# YTM32B1ME0 register map
Vendor: YTMicro; File version: 1.6
CPU: CM33 r0p4, little endian, MPU, FPU, 2 interrupt priority bits
Registers are 32-bit, read-write, reset 0x0 unless marked. A register's access mark holds for its fields unless they carry their own. Offsets are from the block's base; [hi:lo] are bit positions; {n}, {i} and the like mark numbered series; 'fields as' and 'values as' point back to an identical list.

## CAN0 (part 1 of 4) — FlexCAN module
Base 0x40030000; register names take the prefix CAN0_
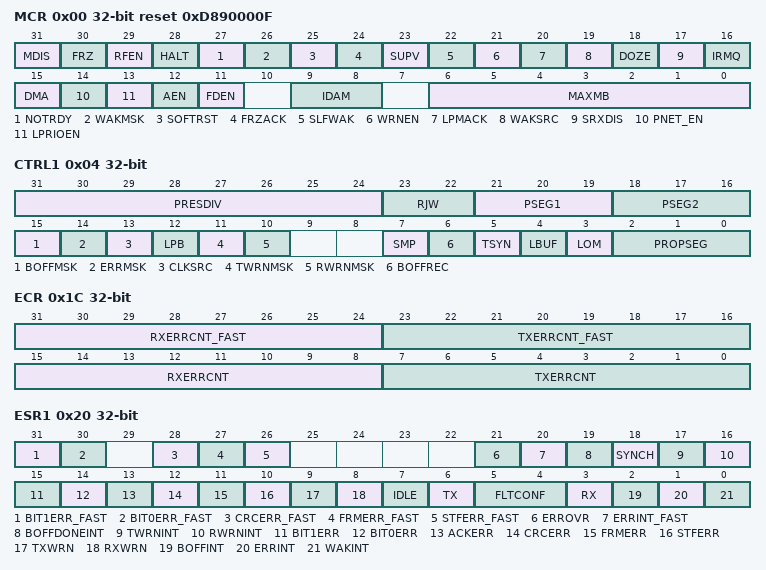
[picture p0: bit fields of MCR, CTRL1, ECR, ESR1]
0x00 MCR reset 0xD890000F — CAN_MCR defines global system configurations, such as the module operation modes and the maximum message buffer configuration.
  [31] MDIS — When disabled, the FlexCAN disables the clocks to the PE and CHI submodules. MDIS is not affected by soft reset.
    0=Enable the FlexCAN module; 1=Disable the FlexCAN module
  [30] FRZ — The FRZ bit specifies the FlexCAN behavior when CAN_MCR.HALT is set or when Debug mode is requested at chip level. When FRZ is asserted, the FlexCAN is enabled to enter Freeze mode. Negation of FRZ causes the FlexCAN to exit from Freeze mode. FRZ is set by hardware when a non-correctable error is detected and CAN_MECR.NCEFAFRZ is asserted.
    0=Not enabled to enter freeze mode; 1=Enabled to enter freeze mode
  [29] RFEN — When RFEN is set, MBs 0-5 cannot be used for normal reception and transmission because the corresponding memory region (0x80-0xDC) is used by the FIFO engine and additional MBs (up to 32, depending on CAN_CTRL2.RFFN setting), which are used as Legacy Rx FIFO ID Filter Table elements. RFEN also impacts the minimum number of peripheral clocks per CAN bit. RFEN can be written in Freeze mode only because it is blocked by hardware in other modes. NOTE: RFEN cannot be set when CAN FD operation is enabled (see FDEN bit).
    0=Disable Rx FIFO; 1=Enable Rx FIFO
  [28] HALT — Assertion of HALT puts the FlexCAN module into Freeze mode. The CPU should clear HALT after initializing the message buffers and the control registers CAN_CTRL1 and CAN_CTRL2. No reception or transmission is performed by the FlexCAN before HALT is cleared. Freeze mode cannot be entered when the FlexCAN is in a low-power mode. The HALT bit is set by hardware when a non-correctable error is detected and CAN_MECR.NCEFAFRZ is asserted.
    0=No Freeze mode request; 1=Enter Freeze mode if the FRZ bit is asserted
  [27] NOTRDY ro — NOTRDY is a read-only bit that indicates that the FlexCAN is either in Module Disable, Doze, Deepsleep, or Freeze mode. NOTRDY is negated when the FlexCAN has exited these modes. NOTRDY bit is not affected by soft reset
    0=FlexCAN is either in Normal, Listen-Only or Loop-Back mode; 1=FlexCAN is either in Module Disable, Doze, Deepsleep or Freeze mode
  [26] WAKMSK — Enables Wake Up interrupt generation under the Self Wake Up mechanism:
    0=Disable Wake Up interrupt; 1=Enable Wake Up interrupt
  [25] SOFTRST — When SOFTRST is asserted, the FlexCAN resets its internal state machines and some of the memory-mapped registers. SOFTRST can be asserted directly by the CPU by writing to CAN_MCR. SOFTRST is also asserted when global soft reset is requested at chip level. Because soft reset is synchronous and has to follow a request/acknowledge procedure across clock domains, it may take some time to fully propagate its effect. The SOFTRST bit remains asserted while reset is pending, and is automatically negated when reset completes. Therefore, software can poll SOFTRST to know when the soft reset has completed. Soft reset cannot be applied when clocks are shut down in a low-power mode. The FlexCAN should be first removed from low-power mode, then soft reset can be applied. SOFTRST is not affected by soft reset
    0=No reset request; 1=Reset the registers affected by software reset
  [24] FRZACK ro — FRZACK is a read-only bit that indicates that the FlexCAN is in Freeze mode and its prescaler is stopped. A Freeze mode request cannot be granted until current transmission or reception processes have finished. Therefore, software can poll FRZACK to know when the FlexCAN has actually entered Freeze mode. If the Freeze mode request is negated, FRZACK is negated after the FlexCAN prescaler is running again. If Freeze mode is requested when the FlexCAN is in a low-power mode, FRZACK will be set only when the low-power mode is exited. See \hyperref[freeze-mode]{"Freeze Mode"}. FRZACK is not affected by soft reset. NOTE: FRZACK is asserted within 178 CAN bits from the Freeze mode request by the CPU, and negated within 2 CAN bits after the Freeze mode request removal (see \hyperref[protocol-timing]{"Protocol Timing"}).
    0=FlexCAN not in Freeze Mode, prescaler running; 1=FlexCAN in Freeze Mode, prescaler stopped
  [23] SUPV — The registers affected by SUPV are marked as S/U in the Access Type column of Table: \hyperref[CAN-register-access-and-reset-information]{"CAN register access and reset information"}. The SUPV reset value is 1, so the affected registers start with Supervisor access only. SUPV can be written only in Freeze mode because it is blocked by hardware in other modes.
    1=FlexCAN is in Supervisor Mode, Affected registers allow only Supervisor access. Unrestricted access behaves as though the access was done to an unimplemented register location.; 0=FlexCAN is in User mode, Affected registers allow both Supervisor and Unrestricted accesses
  [22] SLFWAK — When the Self Wake Up feature is enabled, the FlexCAN module monitors the bus for wakeup event (a recessive-to-dominant transition). If a wakeup event is detected during Deepsleep mode, the FlexCAN, if enabled to do so, generates a Wake Up interrupt to the CPU so that it can exit Deepsleep mode globally and the FlexCAN can request to resume the clocks. When FlexCAN is in a low-power mode other than Module Disable, SLFWAK cannot be written as it is blocked by hardware. When Pretended Networking mode is set, Self Wake Up must be disabled.
    1=Enable FlexCAN self Wake Up feature; 0=Disable FlexCAN self Wake Up feature
  [21] WRNEN — Assertion of WRNEN enables the generation of the TWRNINT and RWRNINT flags in the Error and Status Register 1 (CAN_ESR1). If WRNEN is negated, the TWRNINT and RWRNINT flags will always be zero, independent of the values of the error counters, and no warning interrupt will ever be generated. WRNEN can be written only in Freeze mode because it is blocked by hardware in other modes.
    1=TWRNINT and RWRNINT bits are set when the respective error counter transitions from less than 96 to greater than or equal to 96; 0=TWRNINT and RWRNINT bits are zero, independent of the values in the error counters
  [20] LPMACK ro — LPMACK is a read-only bit that indicates that the FlexCAN is in a low-power mode (Module Disable, Doze or Deepsleep). A low-power mode cannot be entered until all current transmission or reception processes have finished. Therefore, the CPU can poll LPMACK to know when the FlexCAN has actually entered low-power mode. LPMACK is not affected by soft reset. NOTE: LPMACK is asserted within 180 CAN bits from the low-power mode request by the CPU, and negated within 2 CAN bits after the low-power mode request removal (see \hyperref[protocol-timing]{"Protocol Timing"}). When the FlexCAN is in Pretended Networking mode, LPMACK is negated within 180 CAN bits after the low-power mode request removal.
    1=FlexCAN is in the low-power mode; 0=FlexCAN is not in the low-power mode
  [19] WAKSRC — WAKSRC can be written only in Freeze mode because it is blocked by hardware in other modes.
    1=FlexCAN uses the filtered RX input to detect recessive to dominant edges on the can bus; 0=FlexCAN uses the unfiltered RX input to detect recessive to dominant edges on the can bus
  [18] DOZE — DOZE is automatically reset when the FlexCAN wakes up from Doze mode upon detecting activity on the CAN bus (Self Wake Up enabled).
    1=FlexCAN is enabled to enter low-power mode when Doze mode is requested; 0=FlexCAN is not enabled to enter low-power mode when Doze mode is requested
  [17] SRXDIS — SRXDIS controls whether the FlexCAN is allowed to receive frames transmitted by itself. If SRXDIS is asserted, frames transmitted by the FlexCAN are not stored in any MB, regardless of whether the MB is programmed with an ID that matches the transmitted frame, and no interrupt flag or interrupt signal is generated due to the frame reception. SRXDIS can be written only in Freeze mode because it is blocked by hardware in other modes
    1=Disable self-reception; 0=Enable self-reception
  [16] IRMQ — IRMQ controls whether Rx matching process is based on individual masking and queue or on masking scheme with CAN_RXMGMASK, CAN_RX14MASK, CAN_RX15MASK, and CAN_RXFGMASK. IRMQ can be written in Freeze mode only because it is blocked by hardware in other modes.
    1=Enable individual Rx masking and queue feature; 0=Disable individual Rx masking and queue feature. For backward compatibility with legacy applications, the reading of C/S word locks the MB even if it is EMPTY
  [15] DMA — The DMA bit enables or disables the DMA feature. The DMA feature can only be used with the Legacy Rx FIFO or the Enhanced Rx FIFO; consequently, either CAN_MCR.RFEN or CAN_ERFCR.ERFEN must be asserted. When DMA and RFEN are both set, CAN_IFLAG1.BUF5I generates the DMA request and no Rx FIFO interrupt is generated. The DMA bit can be written in Freeze mode only as it is blocked by hardware in other modes. The DMA bit is not available(reserved, write 0) if parameter DMA_EN is 0
    1=Enable DMA feature for Rx FIFO; 0=Disable DMA feature for Rx FIFO
  [14] PNET_EN — When Pretended Networking is enabled, the PE submodule is kept operational in Doze mode and Deepsleep mode, so that it is able to process Rx message filtering as defined by the Pretended Networking configuration registers. See \hyperref[receive-process-under-pretended-networking-mode]{"Receive Process under Pretended Networking Mode"}. PNET_EN can be written in Freeze mode only. The PNET_EN bit is not available (reserved, write 0) if parameter PNET_EN is 0.
    1=Enable Pretended Networking mode; 0=Disable Pretended Networking mode
  [13] LPRIOEN — The LPRIOEN bit is provided for backward compatibility with legacy applications. LPRIOEN controls whether the Local Priority feature is enabled or not. Local Priority is used to expand the ID used during the arbitration process. With this expanded ID concept, the arbitration process is done based on the full 32-bit word, but the actual transmitted ID still has 11 bits for standard frames and 29 bits for extended frames. LPRIOEN can be written only in Freeze mode because it is blocked by hardware in other modes.
  [12] AEN — The Tx abort mechanism ensures a safe procedure for aborting a pending transmission, so that no frame is sent on the CAN bus without notification. See \hyperref[transmission-abort-mechanism]{"Transmission Abort Mechanism"}. AEN can be written only in Freeze mode because it is blocked by hardware in other modes. NOTE: When AEN is asserted, the abort mechanism must only be used for updating mailboxes configured for transmission. Caution: Writing the Abort code into Rx mailboxes can cause unpredictable results when AEN is asserted.
    1=Enable abort; 0=Disable abort
  [11] FDEN — FDEN can be written in Freeze mode only. The FEDN bit is not available (reserved, write 0) if parameter FD_EN is 0. NOTE: The Rx FIFO Enable (RFEN) bit cannot be set if FDEN is asserted.
    1=CAN FD is enabled. The FlexCAN is able to receive and transmit messages in both CAN FD and CAN 2.0 formats.; 0=CAN FD is disabled. The FlexCAN is able to receive and transmit messages in CAN 2.0 format.
  [9:8] IDAM — All elements of the table are configured at the same time by IDAM (they are all the same format). See \hyperref[legacy-rx-fifo-structure]{"Legacy Rx FIFO Structure"}. IDAM can be written only in Freeze mode because it is blocked by hardware in other modes.
    0=Format A – One full ID (standard and extended) per ID Filter Table element; 1=Format B – Two full standard IDs or two partial 14-bit (standard and extended) IDs per ID Filter Table element; 2=Format C – Four partial 8-bit standard IDs per ID Filter Table element; 3=Format D – All frames rejected
  [6:0] MAXMB — The reset value (0x0F) is equivalent to a 16 message buffer configuration. MAXMB can be written only in Freeze mode because it is blocked by hardware in other modes. Number of the last MB = MAXMB NOTE: MAXMB must be programmed with a value smaller than or equal to the number of available message buffers, as described in \hyperref[flexcan-memory-partition-for-can-fd]{"FlexCAN Memory Partition for CAN FD"}. Additionally, the definition of MAXMB value must take into account the region of MBs occupied by Rx FIFO and its ID filters table space defined by CAN_CTRL2.RFFN. MAXMB also impacts the minimum number of peripheral clocks per CAN bit as described in the FlexCAN Integration Guide.
0x04 CTRL1 — The CAN_CTRL1 register is defined for specific FlexCAN control features related to the CAN bus, such as bit-rate, programmable sampling point within an Rx bit, Loop-Back mode, Listen-Only mode, Bus Off recovery behavior, and interrupt enabling (Bus Off, Error, Warning). It also determines the division factor for the clock prescaler. The CAN bit timing variables (PRESDIV, PROPSEG, PSEG1, PSEG2, and RJW) can also be configured in CAN_CBT register, which extends the range of all these variables. If CAN_CBT.BTF is set, the PRESDIV, PROPSEG, PSEG1, PSEG2, and RJW fields of CAN_CTRL1 become read-only. When CAN_CTRL2.BTE = 1, the PRESDIV, PROPSEG, PSEG1, PSEG2, and RJW fields in CAN_CTRL1 are not used. They are read as zero and a write operation to them has no effect. NOTE: When the CAN FD feature is enabled, do not use the PRESDIV, RJW, PSEG1, PSEG2, and PROPSEG fields of the CAN_CTRL1 register for CAN bit timing. Instead, use the CAN_CBT register’s EPRESDIV, ERJW, EPSEG1, EPSEG2, and EPROPSEG fields. The contents of the CAN_CTRL1 register are not affected by soft reset. NOTE: The CAN bit variables in CAN_CTRL1 and in CAN_CBT are stored in the same register.
  [31:24] PRESDIV — The Sclock period defines the time quantum of the CAN protocol. For the reset value, the Sclock frequency is equal to the PE clock frequency. The maximum value of PRESDIV is 0xFF, which gives a minimum Sclock frequency equal to the PE clock frequency divided by 256. See section \hyperref[protocol-timing]{"Protocol Timing"}. PRESDIV can be written only in Freeze mode because it is blocked by hardware in other modes. Sclock frequency = PE clock frequency / (PRESDIV + 1)
  [23:22] RJW — One time quantum is equal to the Sclock period. The valid programmable values for RJW are 0–3. RJW can be written only in Freeze mode because it is blocked by hardware in other modes. Resync Jump Width = RJW + 1
  [21:19] PSEG1 — The valid programmable values are 0–7. PSEG1 can be written only in Freeze mode because it is blocked by hardware in other modes. Phase Buffer Segment 1 = (PSEG1 + 1) × Time-Quanta
  [18:16] PSEG2 — The valid programmable values are 1–7. PSEG2 can be written only in Freeze mode because it is blocked by hardware in other modes. Phase Buffer Segment 2 = (PSEG2 + 1) × Time-Quanta
  [15] BOFFMSK
    0=Bus Off interrupt disabled; 1=Bus Off interrupt enabled
  [14] ERRMSK
    0=Error interrupt disabled; 1=Error interrupt enabled
  [13] CLKSRC — The selected clock is fed to the prescaler to generate the serial clock (Sclock). To ensure reliable operation, CLKSRC can be written only in Disable mode. In other modes, writing to CLKSRC is blocked by hardware. See \hyperref[protocol-timing]{"Protocol Timing"}.
    0=The PE clock source is the oscillator clock. Under this condition, the oscillator clock frequency must be lower than the peripheral clock frequency.; 1=The PE clock source is the peripheral clock
  [12] LPB — In Loop-Back mode, the FlexCAN performs an internal loop back that can be used for self-test operation. The bit stream output of the transmitter is fed back internally to the receiver input. The Rx CAN input pin is ignored and the Tx CAN output goes to the recessive state (logic 1). The FlexCAN behaves as it normally does when transmitting, and treats its own transmitted message as a message received from a remote node. In Loop-Back mode, the FlexCAN ignores the bit sent during the ACK slot in the CAN frame acknowledge field, generating an internal acknowledge bit to ensure proper reception of its own message. Both transmit and receive interrupts are generated. LPB can be written only in Freeze mode because it is blocked by hardware in other modes. NOTE: In Loop-Back mode, CAN_MCR.SRXDIS cannot be asserted because it would impede the self-reception of a transmitted message. NOTE: CAN_FDCTRL.TDCEN must be 0 (Transceiver Delay Compensation feature disabled) when LPB is asserted.
    0=Loop-Back disabled; 1=Loop-Back enabled
  [11] TWRNMSK — TWRNMSK is read as zero when CAN_MCR.WRNEN is negated. TWRNMSK can be written only if CAN_MCR.WRNEN is asserted
    0=Tx Warning interrupt disabled; 1=Tx Warning interrupt enabled
  [10] RWRNMSK — RWRNMSK is read as zero when CAN_MCR.WRNEN is negated. RWRNMSK can be written only if CAN_MCR.WRNEN is asserted.
    0=Rx Warning interrupt disabled; 1=Rx Warning interrupt enabled
  [7] SMP — SMP can be written only in Freeze mode because it is blocked by hardware in other modes. NOTE: For proper operation, to assert SMP it is necessary to guarantee a minimum value of two time quanta in CAN_CTRL1.PSEG1 (or CAN_CBT.EPSEG1). SMP cannot be asserted when CAN FD is enabled (CAN_MCR.FDEN = 1).
    0=One sample is used to determine the bit value; 1=Three samples are used to determine the value of the received bit, the regular sample (sample point) and two preceding samples; a majority rule is used
  [6] BOFFREC — If BOFFREC is negated, automatic recovering from Bus Off state occurs according to the CAN Specification 2.0B. If BOFFREC is asserted, automatic recovering from Bus Off is disabled and the FlexCAN module remains in Bus Off state until BOFFREC is negated by software. If the negation occurs before 128 sequences of 11 recessive bits are detected on the CAN bus, then Bus Off recovery happens as if the BOFFREC bit had never been asserted. If the negation occurs after 128 sequences of 11 recessive bits occurred, then the FlexCAN will re-synchronize to the bus by waiting for 11 recessive bits before joining the bus. After negation, BOFFREC can be re-asserted again during Bus Off, but it will be effective only the next time the FlexCAN module enters Bus Off. If BOFFREC was negated when the FlexCAN module entered Bus Off, asserting BOFFREC during Bus Off will not be effective for the current Bus Off recovery.
    0=Automatic recovering from Bus Off state enabled; 1=Automatic recovering from Bus Off state disabled
  [5] TSYN — The Timer Sync feature provides a means to synchronize multiple FlexCAN stations with a special "SYNC" message (global network time). If CAN_MCR.RFEN is set (Legacy Rx FIFO enabled), the first available mailbox, according to the CAN_CTRL2.RFFN setting, is used for timer synchronization instead of MB0. TSYN can be written in Freeze mode only because it is blocked by hardware in other modes.
    0=Timer Sync feature disabled; 1=Timer Sync feature enabled
  [4] LBUF — When LBUF is asserted, the CAN_MCR.LPRIOEN bit does not affect the priority arbitration. LBUF can be written only in Freeze mode because it is blocked by hardware in other modes.
    0=Buffer with highest priority is transmitted first; 1=Lowest number buffer is transmitted first
  [3] LOM — In Listen-Only mode, transmission is disabled, all error counters described in CAN_ECR are frozen and the FlexCAN module operates in a CAN Error Passive mode. Only messages acknowledged by another CAN station will be received. If the FlexCAN detects a message that has not been acknowledged, it flags a BIT0 error without changing the receive error counter (RXERRCNT) in CAN_ECR, as if it were trying to acknowledge the message. Listen-Only mode is acknowledged by the state of the CAN_ESR1.FLTCONF field indicating Passive Error. There can be some delay between the Listen-Only mode request and acknowledge. LOM can be written in Freeze mode only because it is blocked by hardware in other modes.
    0=Listen-Only mode is deactivated; 1=FlexCAN module operates in Listen-Only mode
  [2:0] PROPSEG — The valid programmable values are 0–7. PROPSEG can be written only in Freeze mode because it is blocked by hardware in other modes. Propagation segment time = (PROPSEG + 1) × time-quanta. Time-quantum = one Sclock period.
0x08 TIMER — The CAN_TIMER register represents a 16-bit free-running counter that can be read and written by the CPU. The timer starts from 0x0 after reset, counts linearly to 0xFFFF, and wraps around. When CAN_CTRL2.TIMER_SRC is asserted, the timer is continuously incremented by an external time tick. The time tick must be synchronous to the peripheral clock, with a minimum pulse width of one ipg_clk cycle. When CAN_CTRL2.TIMER_SRC is negated, the timer is incremented by the CAN bit clock, which defines the baud rate on the CAN bus. During a message transmission/reception, the timer increments by one for each bit that is received or transmitted. When there is no message on the bus, the timer counts using the previously programmed baud rate. The timer is not incremented during Module Disable, Doze, Deepsleep, and Freeze modes. The timer value is captured when the second bit of the identifier field of any frame is on the CAN bus. This captured value is written into the Time Stamp entry in a message buffer after a successful reception or transmission of a message. If CAN_CTRL1.TSYN is asserted, the timer is reset whenever a message is received in the first available mailbox, according to the CAN_CTRL2.RFFN setting. The CPU can write to this register anytime. However, if the write occurs at the same time that the timer is being reset by a reception in the first mailbox, then the write value is discarded. Reading this register affects the mailbox unlocking procedure, see \hyperref[mailbox-lock-mechanism]{"Mailbox Lock Mechanism"}.
  [15:0] TIMER
0x10 RXMGMASK
  [31:0] MG — The MG bits mask the mailbox filter bits. Note that the alignment with the ID word of the mailbox is not perfect as the two most significant MG bits affect the fields RTR and IDE, which are located in the Control and Status (C/S) word of the mailbox. Details see table \hyperref[CAN-which-MG-bits-mask-each-mailbox-filter-field]{CAN which MG bits mask each mailbox filter field} 0b - The corresponding bit in the filter is ``don't care". 1b - The corresponding bit in the filter is checked.
0x14 RX14MASK — The CAN_RX14MASK register is located in RAM. CAN_RX14MASK is provided for legacy application support. When the CAN_MCR.IRMQ bit is asserted, CAN_RX14MASK has no effect. CAN_RX14MASK is used to mask the filter fields of message buffer 14. CAN_RX14MASK can only be programmed when the FlexCAN is in Freeze mode as it is blocked by hardware in other modes.
  [31:0] RX14M — Each mask bit masks the corresponding mailbox 14 filter field in the same way that CAN_RXMGMASK masks other mailboxes’ filters. See the description of the CAN_RXMGMASK register. 0b - The corresponding bit in the filter is ``don't care". 1b - The corresponding bit in the filter is checked.
0x18 RX15MASK — The CAN_RX15MASK register is located in RAM. CAN_RX15MASK is provided for legacy application support. When the CAN_MCR.IRMQ bit is asserted, CAN_RX15MASK has no effect. CAN_RX15MASK is used to mask the filter fields of message buffer 15. CAN_RX15MASK can be programmed only when the FlexCAN is in Freeze mode because it is blocked by hardware in other modes.
  [31:0] RX15M — Each mask bit masks the corresponding mailbox 15 filter field in the same way that CAN_RXMGMASK masks other mailboxes’ filters. See the description of the CAN_RXMGMASK register. 0b - The corresponding bit in the filter is ``don't care". 1b - The corresponding bit in the filter is checked.
0x1C ECR
  [31:24] RXERRCNT_FAST — Receive Error Counter for Fast Bits – Receive error counter for errors detected in the Data Phase of received CAN FD messages with the BRS bit set. The RXERRCNT_FAST counter is read-only except in Freeze mode, in which the CPU can write an 8-bit zero value only. RXERRCNT_FAST is not available (reserved) when configuration parameter FD_EN is 0.
  [23:16] TXERRCNT_FAST — Transmit Error Counter for Fast Bits – Transmit error counter for errors detected in the Data Phase of transmitted CAN FD messages with the BRS bit set. The TXERRCNT_FAST counter is read-only except in Freeze mode, in which the CPU can write a 8-bit zero value only. TXERRCNT_FAST is not available (reserved) when configuration parameter FD_EN is 0.
  [15:8] RXERRCNT — Receive Error Counter – Receive error counter for all errors detected in received messages. The RXERRCNT counter is read-only except in Freeze mode, in which it can be written by the CPU.
  [7:0] TXERRCNT — Transmit Error Counter – Transmit error counter for all errors detected in transmitted messages. The TXERRCNT counter is read-only except in Freeze mode, in which it can be written by the CPU.
0x20 ESR1
  [31] BIT1ERR_FAST ro — BIT1ERR_FAST indicates when an inconsistency occurs between the transmitted and the received bit in the Data Phase of CAN FD frames with the BRS bit set. BIT1ERR_FAST is not available (reserved) when configuration parameter FD_EN is 0.
    0=No such occurrence; 1=At least one bit sent as recessive is received as dominant
  [30] BIT0ERR_FAST ro — BIT0ERR_FAST indicates when an inconsistency occurs between the transmitted and the received bit in the Data Phase of CAN FD frames with the BRS bit set. BIT0ERR_FAST is not available (reserved) when configuration parameter FD_EN is 0.
    values as BIT1ERR_FAST
  [28] CRCERR_FAST ro — CRCERR_FAST indicates that a CRC error has been detected by the receiver node in the CRC field of CAN FD frames with the BRS bit set; that is, the calculated CRC is different from the received CRC. CRCERR_FAST is not available (reserved) when configuration parameter FD_EN is 0.
    0=No such occurrence; 1=A CRC error occurred since last read of this register
  [27] FRMERR_FAST ro — FRMERR_FAST indicates that a form error has been detected by the receiver node in the Data Phase of CAN FD frames with the BRS bit set; that is, a fixed-form bit field contains at least one illegal bit. FRMERR_FAST is not available (reserved) when configuration parameter FD_EN is 0.
    0=No such occurrence; 1=A form error occurred since last read of this register
  [26] STFERR_FAST ro — STFERR_FAST indicates that a stuffing error has been detected in the Data Phase of CAN FD frames with the BRS bit set. STFERR_FAST is not available (reserved) when configuration parameter FD_EN is 0.
    0=No such occurrence; 1=A stuffing error occurred since last read of this register
  [21] ERROVR — ERROVR is cleared by writing 1 to it.
    0=Overrun has not occurred; 1=Overrun has occurred
  [20] ERRINT_FAST — ERRINT_FAST indicates that at least one of the error bits detected in the Data Phase of CAN FD frames with the BRS bit set (BIT1ERR_FAST, BIT0ERR_FAST, CRCERR_FAST, FRMERR_FAST, or STFERR_FAST) is set. If the corresponding mask bit (CAN_CTRL2.ERRMSK_FAST) is set, an interrupt is generated to the CPU. ERRINT_FAST is cleared by writing 1 to it. Writing 0 has no effect. ERRINT_FAST is not available (reserved) when configuration parameter FD_EN is 0.
    0=No such occurrence; 1=Indicates setting of any error bit detected in the Data Phase of CAN FD frames with the BRS bit set
  [19] BOFFDONEINT — BOFFDONEINT is set when the Tx Error Counter (TXERRCNT) has finished counting 128 occurrences of 11 consecutive recessive bits on the CAN bus and is ready to leave Bus Off. If the corresponding mask bit (CAN_CTRL2.BOFFDONEMSK) is set, an interrupt is generated to the CPU. BOFFDONEINT is cleared by writing 1 to it. Writing 0 has no effect.
    0=No such occurrence; 1=FlexCAN module has completed Bus Off process
  [18] SYNCH ro — SYNCH is a read-only flag that indicates whether the FlexCAN is synchronized to the CAN bus and able to participate in the communication process. It is set and cleared by the FlexCAN. See \hyperref[CAN-state-related-bit-encodings]{CAN state related bit encodings}
    0=FlexCAN is not synchronized to the CAN bus; 1=FlexCAN is synchronized to the CAN bus
  [17] TWRNINT — If CAN_MCR.WRNEN is asserted, the TWRNINT bit is set when the TXWRN flag transitions from 0 to 1, meaning that the Tx error counter reached 96. If the corresponding mask bit (CAN_CTRL1.TWRNMSK) is set, an interrupt is generated to the CPU. TWRNINT is cleared by writing 1 to it. Writing 0 has no effect. When CAN_MCR.WRNEN is negated, the TWRNINT flag is masked. The CPU must clear the TWRNINT flag before negating CAN_MCR.WRNEN. Otherwise, TWRNINT will be set when CAN_MCR.WRNEN is set again. TWRNINT is not generated during the Bus Off state and is not updated during Freeze mode. When the FlexCAN returns to Normal mode from Pretended Networking mode, TWRNINT is not updated. See \hyperref[receive-process-under-pretended-networking-mode]{"Receive Process under Pretended Networking Mode"}.
    0=No such occurrence; 1=The Tx error counter transitioned from less than 96 to greater than or equal to 96
  [16] RWRNINT — If CAN_MCR.WRNEN is asserted, the RWRNINT bit is set when the RXWRN flag transitions from 0 to 1, meaning that the Rx error counters reached 96. If the corresponding mask bit (CAN_CTRL1.RWRNMSK) is set, an interrupt is generated to the CPU. RWRNINT is cleared by writing it to 1 to it. Writing 0 has no effect. When CAN_MCR.WRNEN is negated, the RWRNINT flag is masked. The CPU must clear the RWRNINT flag before negating CAN_MCR.WRNEN. Otherwise, RWRNINT will be set when CAN_MCR.WRNEN is set again. RWRNINT is not updated during Freeze mode. When the FlexCAN returns to Normal mode from Pretended Networking mode, RWRNINT is updated to reflect the Rx error counter state. See \hyperref[receive-process-under-pretended-networking-mode]{"Receive Process under Pretended Networking Mode"}
    0=No such occurrence; 1=The Rx error counter transitioned from less than 96 to greater than or equal to 96
  [15] BIT1ERR ro — NOTE: BIT1ERR is not set by a transmitter in case of arbitration field or ACK slot, or in case of a node sending a passive error flag that detects dominant bits. BIT1ERR is updated when the FlexCAN returns to Normal mode from Pretended Networking mode.
  [14] BIT0ERR ro — BIT0ERR is updated when the FlexCAN returns to Normal mode from Pretended Networking mode.
    0=No such occurrence; 1=At least one bit sent as dominant is received as recessive
  [13] ACKERR ro — ACKERR is updated when the FlexCAN returns to Normal mode from Pretended Networking mode.
    0=No such occurrence; 1=An ACK error occurred since last read of this register
  [12] CRCERR ro — CRCERR is updated when the FlexCAN returns to Normal mode from Pretended Networking mode.
    values as CRCERR_FAST
  [11] FRMERR ro — FRMERR is updated when the FlexCAN returns to Normal mode from Pretended Networking mode.
    values as FRMERR_FAST
  [10] STFERR ro — STFERR is updated when the FlexCAN returns to Normal mode from Pretended Networking mode.
    values as STFERR_FAST
  [9] TXWRN ro — TXWRN is affected by the value of CAN_ECR.TXERRCNT only. TXWRN is not updated during Freeze mode. TXWRN is updated when the FlexCAN returns to Normal mode from Pretended Networking mode.
    0=No such occurrence; 1=TXERRCNT is greater than or equal to 96
  [8] RXWRN ro — RXWRN is affected by the value of CAN_ECR.RXERRCNT only. RXWRN is not updated during Freeze mode. RXWRN is updated when the FlexCAN returns to Normal mode from Pretended Networking mode.
    0=No such occurrence; 1=RXERRCNT is greater than or equal to 96
  [7] IDLE ro — Indicates when the CAN bus is in the IDLE state. See \hyperref[CAN-state-related-bit-encodings]{CAN state related bit encodings}
    0=No such occurrence; 1=CAN bus is now IDLE
  [6] TX ro — Indicates if the FlexCAN is transmitting a message. See \hyperref[CAN-state-related-bit-encodings]{CAN state related bit encodings}
    0=FlexCAN is not transmitting a message; 1=FlexCAN is transmitting a message
  [5:4] FLTCONF ro — If CAN_CTRL1.LOM is asserted, after a delay that depends on the CAN bit timing, the FLTCONF field will indicate Error Passive. The same delay affects how FLTCONF reflects an update to the CAN_ECR register by the CPU. It may take up to one CAN bit time to get them coherent again. FLTCONF is affected by soft reset. However, if CAN_CTRL1.LOM is asserted, the FLTCONF reset value lasts just one CAN bit. After this time, FLTCONF indicates Error Passive.
    0=Error Active; 1=Error Passive; 2=Bus Off; 3=Bus Off
  [3] RX ro — Indicates if the FlexCAN is receiving a message. See \hyperref[CAN-state-related-bit-encodings]{CAN state related bit encodings}
    0=FlexCAN is not receiving a message; 1=FlexCAN is receiving a message
  [2] BOFFINT — BOFFINT is set when the FlexCAN enters the Bus Off state. If the corresponding mask bit (CAN_CTRL1.BOFFMSK) is set, an interrupt is generated to the CPU. BOFFINT is cleared by writing 1 to it. Writing 0 has no effect.
    0=No such occurrence; 1=FlexCAN module entered Bus Off state
  [1] ERRINT — ERRINT indicates that at least one of the error bits (BIT1ERR, BIT0ERR, ACKERR, CRCERR, FRMERR, or STFERR) is set. If the corresponding mask bit (CAN_CTRL1.ERRMSK) is set, an interrupt is generated to the CPU. ERRINT is cleared by writing 1 to it. Writing 0 has no effect.
    0=No such occurrence; 1=Indicates setting of any error bit in CAN_ESR1
  [0] WAKINT — When a recessive-to-dominant transition is detected on the CAN bus and the CAN_MCR.WAKMSK bit is set, an interrupt is generated to the CPU. This bit is cleared by writing it to 1. When CAN_MCR.SLFWAK is negated, the WAKINT flag is masked. The CPU must clear the WAKINT flag before negating the CAN_MCR.SLFWAK bit. Otherwise, WAKINT will be set when CAN_MCR.SLFWAK is set again. Writing 0 has no effect. WAKINT is cleared by writing 1 to it. Writing 0 has no effect.
    0=No such occurrence; 1=Indicates a recessive-to-dominant transition was received on the CAN bus
0x24 IMASK2 — The CAN_IMASK2 register allows any number of the 32 message buffer interrupts to be enabled or disabled for MB63 to MB32. CAN_IMASK2 contains one interrupt mask bit per buffer, enabling the CPU to determine which buffer generates an interrupt after a successful transmission or reception (as indicated by the corresponding CAN_IFLAG2 bit). The CAN_IMASK2 register is not available if parameter NUMBER_OF_MB is less than 64.
  [31:0] BUF63TO32M — Each bit enables or disables the corresponding FlexCAN Message Buffer Interrupt for MB63 to MB32. NOTE: Setting or clearing a bit in CAN_IMASK2 can assert or negate an interrupt request if the corresponding CAN_IFLAG2 bit is set. 0b - The corresponding buffer interrupt is disabled. 1b - The corresponding buffer interrupt is enabled.
0x28 IMASK1 — The CAN_IMASK1 register allows any number of the 32 message buffer interrupts to be enabled or disabled for MB31 to MB0. CAN_IMASK1 contains one interrupt mask bit per buffer, enabling the CPU to determine which buffer generates an interrupt after a successful transmission or reception (as indicated by the corresponding CAN_IFLAG1 bit).
  [31:0] BUF31TO0M — Each bit enables or disables the corresponding FlexCAN Message Buffer Interrupt for MB31 to MB0. NOTE: Setting or clearing a bit in CAN_IMASK1 can assert or negate an interrupt request if the corresponding CAN_IFLAG1 bit is set. 0b - The corresponding buffer interrupt is disabled. 1b - The corresponding buffer interrupt is enabled.
0x2C IFLAG2 — The CAN_IFLAG2 register defines the flags for the 32 message buffer interrupts for MB63 to MB32. CAN_IFLAG2 contains one interrupt flag bit per buffer. Each successful transmission or reception sets the respective CAN_IFLAG2 bit. If the corresponding CAN_IMASK2 bit is set, an interrupt will be generated. The interrupt flag must be cleared by writing 1 to it. Writing 0 has no effect. Before updating the CAN_MCR.MAXMB field, the CPU must service the CAN_IFLAG2 bits whose MB value is greater than the CAN_MCR.MAXMB to be updated; otherwise, they will remain set and be inconsistent with the number of MBs available. The CAN_IFLAG2 register is not available if parameter NUMBER_OF_MB is less than 64.
  [31:0] BUF63TO32I — Each bit flags the corresponding FlexCAN Message Buffer Interrupt for MB63 to MB32. 0b - The corresponding buffer has no occurrence of successfully completed transmission or reception. 1b - The corresponding buffer has successfully completed transmission or reception.
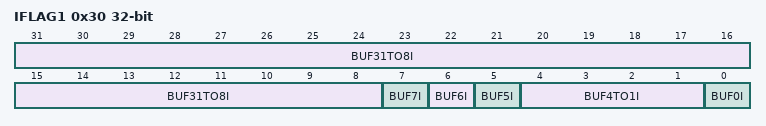
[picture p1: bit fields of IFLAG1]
0x30 IFLAG1
  [31:8] BUF31TO8I — Each bit flags the corresponding FlexCAN Message Buffer Interrupt for MB31 to MB8. Only the lower 8 bits are available if parameter NUMBER_OF_MB is 16. 0b - The corresponding buffer has no occurrence of successfully completed transmission or reception. 1b - The corresponding buffer has successfully completed transmission or reception.
  [7] BUF7I — When CAN_MCR.RFEN is cleared (Legacy Rx FIFO disabled), BUF71 flags the interrupt for MB7. When CAN_MCR.RFEN is set (Legacy Rx FIFO enabled), BUF7I represents Legacy Rx FIFO Overflow. In this case, BUF7I indicates that a message was lost because the Legacy Rx FIFO is full. Note that BUF7I is not asserted when the Legacy Rx FIFO is full and the message was captured by a mailbox. NOTE: BUF7I is cleared by the FlexCAN whenever CAN_MCR.RFEN is changed by a CPU write.
    0=No occurrence of MB7 completing transmission/reception when CAN_MCR.RFEN=0, or of Legacy Rx FIFO overflow when CAN_MCR.RFEN=1; 1=MB7 completed transmission/reception when CAN_MCR.RFEN=0, or Legacy Rx FIFO overflow when CAN_MCR.RFEN=1
  [6] BUF6I — When CAN_MCR.RFEN is cleared (Legacy Rx FIFO disabled), BUF6I flags the interrupt for MB6. When CAN_MCR.RFEN is set (Legacy Rx FIFO enabled), BUF6I represents Legacy Rx FIFO Warning. In this case, BUF6I indicates when the number of unread messages in the Legacy Rx FIFO increases from 4 to 5 due to the reception of a new message, meaning that the Legacy Rx FIFO is almost full. Note that if BUF6I is cleared when the number of unread messages is greater than 4, BUF6I is not asserted again until the number of unread messages in the Legacy Rx FIFO decreases to 4 or less. NOTE: BUF6I is cleared by the FlexCAN whenever CAN_MCR.RFEN is changed by a CPU write.
    0=No occurrence of MB6 completing transmission/reception when CAN_MCR.RFEN=0, or of Legacy Rx FIFO almost full when CAN_MCR.RFEN=1; 1=MB6 completed transmission/reception when CAN_MCR.RFEN=0, or Legacy Rx FIFO almost full when CAN_MCR.RFEN=1
  [5] BUF5I — When CAN_MCR.RFEN is cleared (Legacy Rx FIFO disabled), BUF5I flags the interrupt for MB5. When CAN_MCR.RFEN is set (Legacy Rx FIFO enabled), BUF5I represents Frames Available in Legacy Rx FIFO and indicates that at least one frame is available to be read from the Legacy Rx FIFO. When CAN_MCR.DMA is set, BUF5I generates a DMA request and the CPU must not clear BUF5I by writing 1 to it. NOTE: BUF5I is cleared by the FlexCAN whenever CAN_MCR.RFEN is changed by a CPU write.
    0=No occurrence of MB5 completing transmission/reception when CAN_MCR.RFEN=0, or of frame(s) available in the FIFO, when CAN_MCR.RFEN=1; 1=MB5 completed transmission/reception when CAN_MCR.RFEN=0, or frame(s) available in the Legacy Rx FIFO when CAN_MCR.RFEN=1. BUF5I generates a DMA request when both CAN_MCR.RFEN and CAN_MCR.DMA are set.
  [4:1] BUF4TO1I — When CAN_MCR.RFEN is cleared (Legacy Rx FIFO disabled), BUF4TO1I flag the interrupts for MB4 to MB1. When CAN_MCR.RFEN is set (Legacy Rx FIFO enabled), BUF4TO1I flags are reserved. NOTE: BUF4TO1I are cleared by the FlexCAN whenever CAN_MCR.RFEN is changed by a CPU write.
    0=The corresponding buffer has no occurrence of successfully completed transmission or reception when CAN_MCR.RFEN=0; 1=The corresponding buffer has successfully completed transmission or reception when CAN_MCR.RFEN=0
  [0] BUF0I — When CAN_MCR.RFEN is set (Legacy Rx FIFO enabled), BUF0I is used to trigger the clear FIFO operation. This operation empties Legacy Rx FIFO contents. Before performing this operation, the CPU must service all FIFO related IFLAGs. When CAN_MCR.DMA is set (DMA is enabled), this operation also clears the BUF5I flag and consequently aborts the DMA request. The clear FIFO operation occurs when the CPU writes 1 to BUF0I, which is only allowed in Freeze mode and is blocked by hardware in other conditions. When CAN_MCR.RFEN is cleared (Legacy Rx FIFO disabled), BUF0I flags the interrupt for MB0:
    0=MB0 has no occurrence of successfully completed transmission or reception when CAN_MCR.RFEN=0; 1=MB0 has successfully completed transmission or reception when CAN_MCR.RFEN=0

## CAN1 (part 1 of 4) — FlexCAN module
Base 0x40034000; register names take the prefix CAN1_
Registers as CAN0.

## CAN2 (part 1 of 4) — FlexCAN module
Base 0x40038000; register names take the prefix CAN2_
Registers as CAN0.

## CAN3 (part 1 of 4) — FlexCAN module
Base 0x4003C000; register names take the prefix CAN3_
Registers as CAN0.

## CAN4 (part 1 of 4) — FlexCAN module
Base 0x4003D000; register names take the prefix CAN4_
Registers as CAN0.

## CAN5 (part 1 of 4) — FlexCAN module
Base 0x4003E000; register names take the prefix CAN5_
Registers as CAN0.
